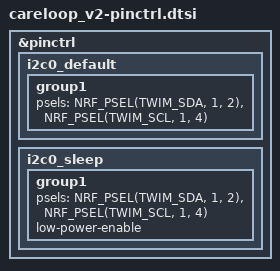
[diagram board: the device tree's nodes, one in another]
/*
 * Copyright (c) 2026 CareLoop
 * SPDX-License-Identifier: Apache-2.0
 *
 * Pin assignments extracted from CareLoop.kicad_sch (v2 hardware).
 * Single shared I2C bus: SDA = P1.02, SCL = P1.04.
 */

&pinctrl {
	i2c0_default: i2c0_default {
		group1 {
			psels = <NRF_PSEL(TWIM_SDA, 1, 2)>,
				<NRF_PSEL(TWIM_SCL, 1, 4)>;
		};
	};

	i2c0_sleep: i2c0_sleep {
		group1 {
			psels = <NRF_PSEL(TWIM_SDA, 1, 2)>,
				<NRF_PSEL(TWIM_SCL, 1, 4)>;
			low-power-enable;
		};
	};
};
